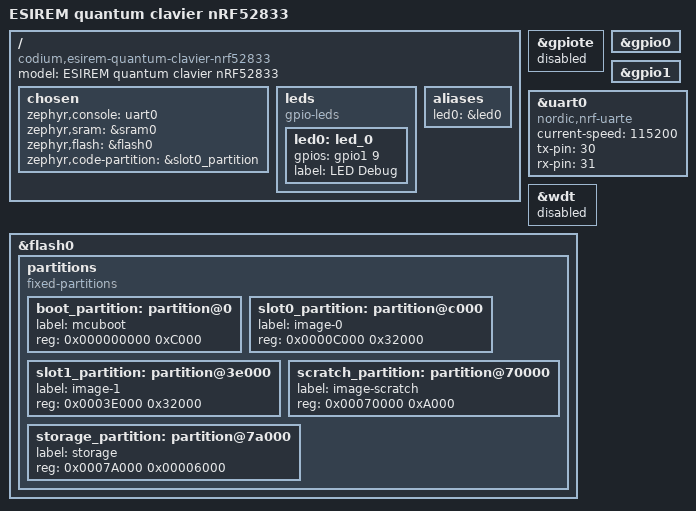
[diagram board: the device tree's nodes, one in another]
/*
 * Copyright (c) 2019 Nordic Semiconductor ASA
 *
 * SPDX-License-Identifier: Apache-2.0
 */

/dts-v1/;

/*
 * On prends le fichier du nRF52833 QIAA même si on a le nRF52833
 * QDAA: aucune différence de config (avec SDK NCS 1.7.0)
 * Identification des pins: Numero de la pin pour le port 0, numero
 * de la pin + 32 pour le port 1
 */
#include <nordic/nrf52833_qiaa.dtsi>

/ {
    model = "ESIREM quantum clavier nRF52833";
    compatible = "codium,esirem-quantum-clavier-nrf52833";

    chosen {
        zephyr,console = < &uart0 >;
        zephyr,sram = &sram0;
        zephyr,flash = &flash0;
        zephyr,code-partition = &slot0_partition;
    };

    leds {
        status = "okay";
        compatible = "gpio-leds";
        led0: led_0 {
            gpios = < &gpio1 9  (GPIO_ACTIVE_HIGH | GPIO_PUSH_PULL)>;
            label = "LED Debug";
        };
    };

    aliases {
        led0 = &led0;
    };
};

&gpiote {
    status = "disabled";
};

&gpio0 {
    status = "okay";
};

&gpio1 {
    status = "okay";
};

&uart0 {
    compatible = "nordic,nrf-uarte";
    status = "okay";
    current-speed = <115200>;
    tx-pin = <30>;
    rx-pin = <31>;
};

&wdt {
    status = "disabled";
};

/* nRF52833: pages flash de 4K (4096 bytes), effacement par page. */
&flash0 {
    partitions {
        compatible = "fixed-partitions";
        #address-cells = <1>;
        #size-cells = <1>;

        boot_partition: partition@0 {
            label = "mcuboot";
            reg = <0x000000000 0xC000>;
        };
        slot0_partition: partition@c000 {
            label = "image-0";
            reg = <0x0000C000 0x32000>;
        };
        slot1_partition: partition@3e000 {
            label = "image-1";
            reg = <0x0003E000 0x32000>;
        };
        scratch_partition: partition@70000 {
            label = "image-scratch";
            reg = <0x00070000 0xA000>;
        };
        /* Partition utilisée pour la configuration (paramètres stockés en flash) */
        storage_partition: partition@7a000 {
            label = "storage";
            reg = <0x0007A000 0x00006000>;
        };
    };
};
